# max32625 register map
Vendor: Maxim Integrated; Series: ARMCM4; File version: 1.1
CPU: CM4 r1p0, little endian, no MPU, FPU, 3 interrupt priority bits
Registers are 32-bit, read-write, reset 0x0 unless marked. A register's access mark holds for its fields unless they carry their own. Offsets are from the block's base; [hi:lo] are bit positions; {n}, {i} and the like mark numbered series.

## PTG — Pulse Train Generation
Base 0x40011000
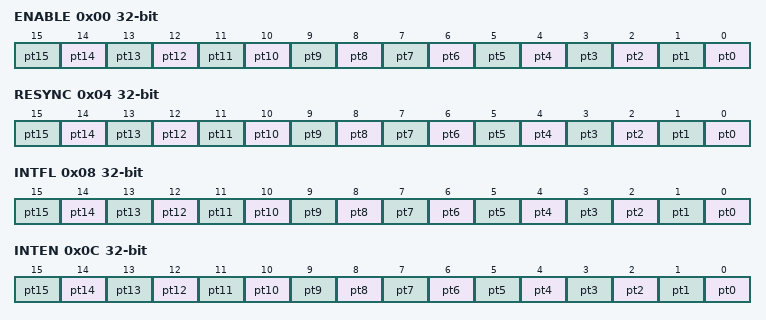
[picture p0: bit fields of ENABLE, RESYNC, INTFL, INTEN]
0x00 ENABLE — Global Enable/Disable Controls for All Pulse Trains
  [n] pt{n} (n=0..15) — Enable/Disable control for PT{n}
0x04 RESYNC — Global Resync (All Pulse Trains) Control
  [n] pt{n} (n=0..15) — Resync control for PT{n}
0x08 INTFL — Pulse Train Interrupt Flags
  [n] pt{n} (n=0..15) — Pulse Train {n} Stopped Interrupt Flag
0x0C INTEN — Pulse Train Interrupt Enable/Disable
  [n] pt{n} (n=0..15) — Pulse Train {n} Stopped Interrupt Enable/Disable

## PT0 — Pulse Train Generation
Base 0x40011010
Same registers: PT{n} {0x40011010+0xC*n} (n=1..15)
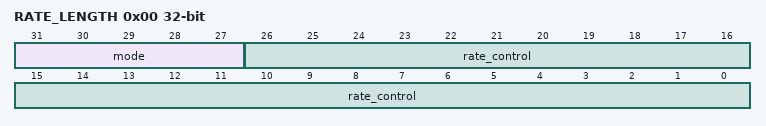
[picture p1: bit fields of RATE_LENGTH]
0x00 RATE_LENGTH — Pulse Train Configuration
  [31:27] mode — Pulse Train Output Mode/Train Length
    0=32_BIT (Pulse train, 32 bit pattern.); 1=SQUARE_WAVE (Square wave mode.); {v}={v}_BIT (Pulse train, {v} bit pattern.) (v=2..31)
  [26:0] rate_control — Pulse Train Enable/Rate Control
0x04 TRAIN — Pulse Train Output Pattern
0x08 LOOP — Pulse Train Loop Count

## I2CM0 — I2C Master 0 Interface
Base 0x40016000
Same registers: I2CM1 0x40017000, I2CM2 0x40018000
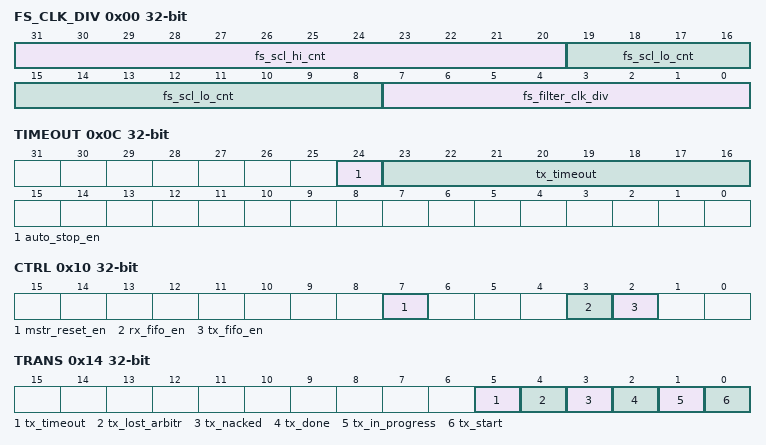
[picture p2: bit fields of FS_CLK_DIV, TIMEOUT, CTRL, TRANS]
0x00 FS_CLK_DIV — Full Speed SCL Clock Settings
  [31:20] fs_scl_hi_cnt — Full Speed SCL High Count
  [19:8] fs_scl_lo_cnt — Full Speed SCL Low Count
  [7:0] fs_filter_clk_div — Full Speed Filter Clock Divisor
0x0C TIMEOUT — Timeout and Auto-Stop Settings
  [24] auto_stop_en — Auto-Stop Enable
  [23:16] tx_timeout — Transaction Timeout Limit
0x10 CTRL — I2C Master Control Register
  [7] mstr_reset_en — Master Reset
  [3] rx_fifo_en — Master Results FIFO Enable
  [2] tx_fifo_en — Master Transaction FIFO Enable
0x14 TRANS — I2C Master Transaction Start and Status Flags
  [5] tx_timeout ro — Transaction Timed Out
  [4] tx_lost_arbitr ro — Transaction Lost Arbitration
  [3] tx_nacked ro — Transaction Nacked
  [2] tx_done ro — Transaction Done
  [1] tx_in_progress ro — Transaction In Progress
  [0] tx_start — Start Transaction
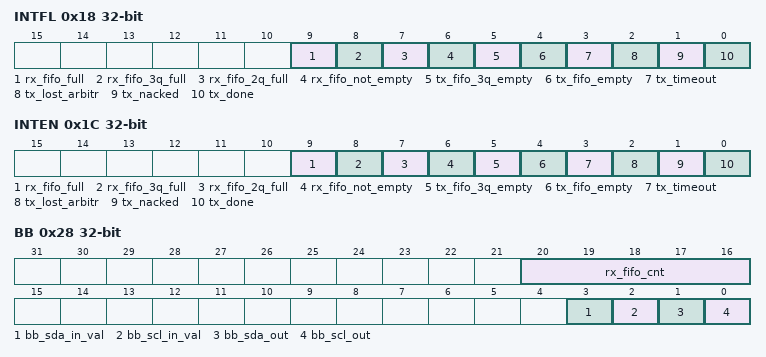
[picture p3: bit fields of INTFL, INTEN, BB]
0x18 INTFL — Interrupt Flags
  [9] rx_fifo_full write-1-clears — Results FIFO Full Int Status
  [8] rx_fifo_3q_full write-1-clears — Results FIFO 3Q Full Int Status
  [7] rx_fifo_2q_full write-1-clears — Results FIFO 2Q Full Int Status
  [6] rx_fifo_not_empty write-1-clears — Results FIFO Not Empty Int Status
  [5] tx_fifo_3q_empty write-1-clears — Transaction FIFO 3Q Empty Int Status
  [4] tx_fifo_empty write-1-clears — Transaction FIFO Empty Int Status
  [3] tx_timeout write-1-clears — Transaction Timed Out Int Status
  [2] tx_lost_arbitr write-1-clears — Transaction Lost Arbitration Int Status
  [1] tx_nacked write-1-clears — Transaction NACKed Int Status
  [0] tx_done write-1-clears — Transaction Done Int Status
0x1C INTEN — Interrupt Enable/Disable Controls
  [9] rx_fifo_full — Results FIFO Full Int Enable
  [8] rx_fifo_3q_full — Results FIFO 3Q Full Int Enable
  [7] rx_fifo_2q_full — Results FIFO 2Q Full Int Enable
  [6] rx_fifo_not_empty — Results FIFO Not Empty Int Enable
  [5] tx_fifo_3q_empty — Transaction FIFO 3Q Empty Int Enable
  [4] tx_fifo_empty — Transaction FIFO Empty Int Enable
  [3] tx_timeout — Transaction Timed Out Int Enable
  [2] tx_lost_arbitr — Transaction Lost Arbitration IntEnable
  [1] tx_nacked — Transaction NACKed Int Enable
  [0] tx_done — Transaction Done Int Enable
0x28 BB — Bit-Bang Control Register
  [20:16] rx_fifo_cnt ro — Results FIFO Data Received Count
  [3] bb_sda_in_val ro — Bit Bang SCL Input Value
  [2] bb_scl_in_val ro — Bit Bang SCL Input Value
  [1] bb_sda_out — Bit Bang SDA Output
  [0] bb_scl_out — Bit Bang SCL Output

## I2CS — I2C Slave Interface
Base 0x40019000
0x00 CLK_DIV — I2C Slave Clock Divisor Control
  [7:0] fs_filter_clock_div — FS Filter Clock Divisor
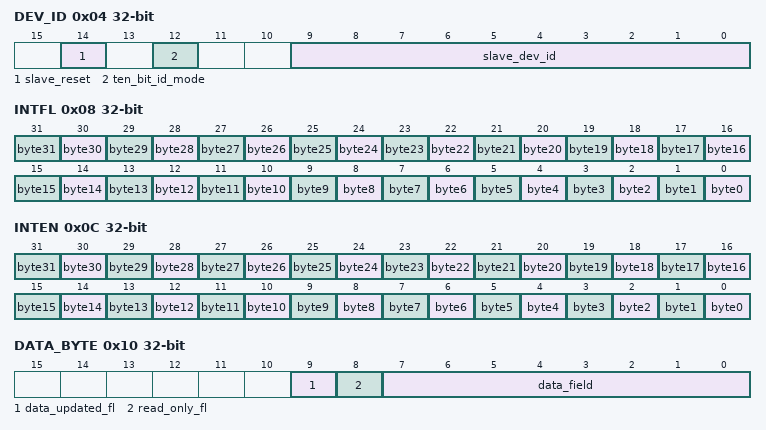
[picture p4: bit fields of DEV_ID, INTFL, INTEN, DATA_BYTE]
0x04 DEV_ID — I2C Slave Device ID Register
  [14] slave_reset
  [12] ten_bit_id_mode — 10-bit ID Mode
  [9:0] slave_dev_id — Slave Device ID
0x08 INTFL — I2CS Interrupt Flags
  [n] byte{n} write-1-clears (n=0..31) — Updated Byte {n}
0x0C INTEN — I2CS Interrupt Enable/Disable Controls
  [n] byte{n} (n=0..31) — Updated Byte {n}
0x10 DATA_BYTE — I2CS Data Byte
  [9] data_updated_fl ro — Byte Updated Flag
  [8] read_only_fl — Read Only Flag
  [7:0] data_field
